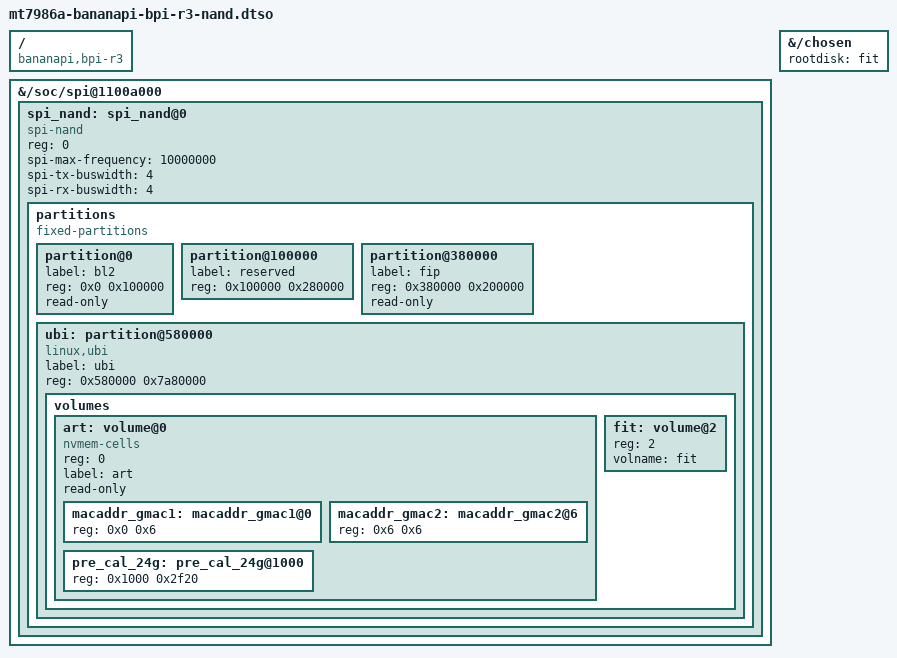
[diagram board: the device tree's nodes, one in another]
/* SPDX-License-Identifier: (GPL-2.0-only OR MIT) */
/*
 * Authors: Daniel Golle <daniel@makrotopia.org>
 *          Frank Wunderlich <frank-w@public-files.de>
 */

/dts-v1/;
/plugin/;

/ {
	compatible = "bananapi,bpi-r3", "mediatek,mt7986a";

	fragment@0 {
		target-path = "/soc/spi@1100a000";
		__overlay__ {
			#address-cells = <1>;
			#size-cells = <0>;
			spi_nand: spi_nand@0 {
				compatible = "spi-nand";
				reg = <0>;
				spi-max-frequency = <10000000>;
				spi-tx-buswidth = <4>;
				spi-rx-buswidth = <4>;

				partitions {
					compatible = "fixed-partitions";
					#address-cells = <1>;
					#size-cells = <1>;

					partition@0 {
						label = "bl2";
						reg = <0x0 0x100000>;
						read-only;
					};

					partition@100000 {
						label = "reserved";
						reg = <0x100000 0x280000>;
					};

					partition@380000 {
						label = "fip";
						reg = <0x380000 0x200000>;
						read-only;
					};

					ubi: partition@580000 {
						label = "ubi";
						reg = <0x580000 0x7a80000>;
						compatible = "linux,ubi";

						volumes {
							#address-cells = <1>;
							#size-cells = <0>;

							art: volume@0 {
								reg = <0>;
								compatible = "nvmem-cells";
								label = "art";
								read-only;
								#address-cells = <1>;
								#size-cells = <1>;

								macaddr_gmac1: macaddr_gmac1@0 {
									reg = <0x0 0x6>;
								};

								macaddr_gmac2: macaddr_gmac2@6 {
									reg = <0x6 0x6>;
								};

								pre_cal_24g: pre_cal_24g@1000 {
									reg = <0x1000 0x2f20>;
								};
							};

							fit: volume@2 {
								reg = <2>;
								volname = "fit";
							};
						};
					};
				};
			};
		};
	};

	fragment@1 {
		target-path = "/chosen";
		__overlay__ {
			rootdisk = <&fit>;
		};
	};
};
